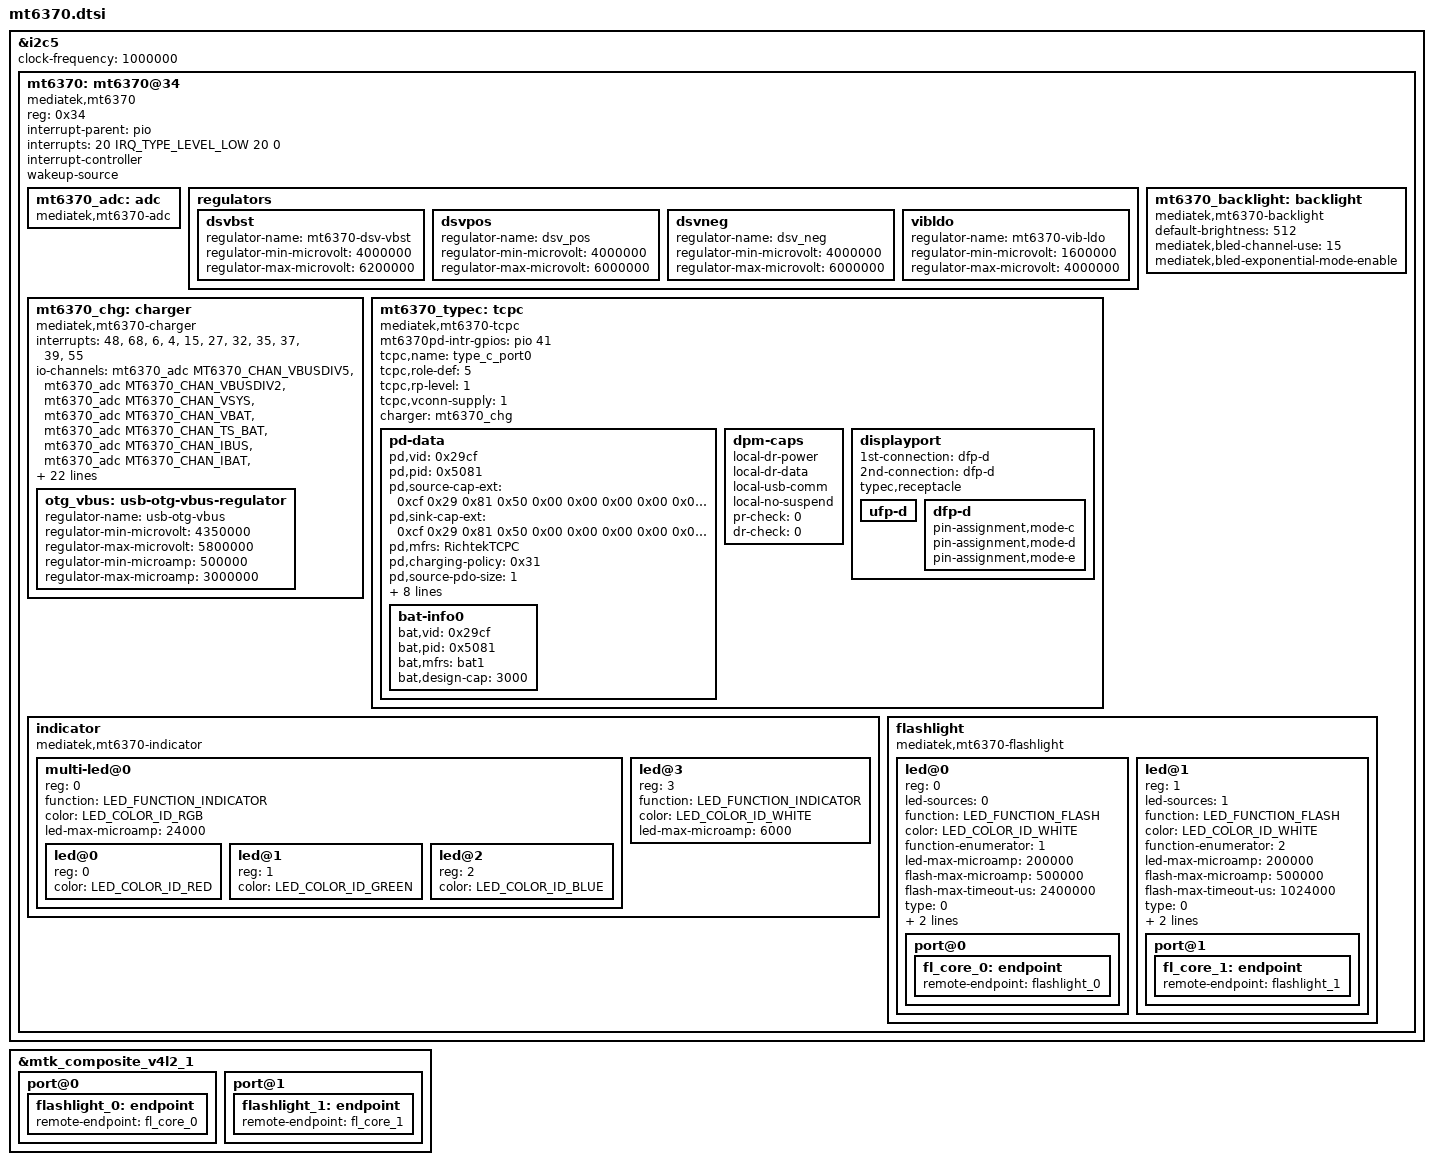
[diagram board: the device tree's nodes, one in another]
// SPDX-License-Identifier: (GPL-2.0 OR MIT)
/*
 * Copyright (c) 2021 MediaTek Inc.
 */

#include <dt-bindings/iio/adc/mediatek,mt6370_adc.h>
#include <dt-bindings/leds/common.h>

&i2c5 {
	clock-frequency = <1000000>;
	mt6370: mt6370@34 {
		compatible = "mediatek,mt6370";
		reg = <0x34>;
		status = "okay";
		interrupt-parent = <&pio>;
		interrupts = <20 IRQ_TYPE_LEVEL_LOW 20 0>;
		interrupt-controller;
		#interrupt-cells = <1>;
		wakeup-source;
		mt6370_adc: adc {
			#io-channel-cells = <1>;
			compatible = "mediatek,mt6370-adc";
		};

		regulators {
			dsvbst {
				regulator-name = "mt6370-dsv-vbst";
				regulator-min-microvolt = <4000000>;
				regulator-max-microvolt = <6200000>;
			};
			dsvpos {
				regulator-name = "dsv_pos";
				regulator-min-microvolt = <4000000>;
				regulator-max-microvolt = <6000000>;
			};
			dsvneg {
				regulator-name = "dsv_neg";
				regulator-min-microvolt = <4000000>;
				regulator-max-microvolt = <6000000>;
			};
			vibldo {
				regulator-name = "mt6370-vib-ldo";
				regulator-min-microvolt = <1600000>;
				regulator-max-microvolt = <4000000>;
			};
		};

		mt6370_chg: charger {
			compatible = "mediatek,mt6370-charger";
			interrupts = <48>, <68>, <6>, <4>, <15>, <27>, <32>, <35>, <37>, <39>, <55>;
			interrupt-names = "attach_i", "uvp_d_evt", "mivr", "treg",
					  "vbusov", "tmri", "aiclmeasi", "wdtmri",
					  "rechgi", "ieoci", "dcdti";
			io-channels = <&mt6370_adc MT6370_CHAN_VBUSDIV5>,
				      <&mt6370_adc MT6370_CHAN_VBUSDIV2>,
				      <&mt6370_adc MT6370_CHAN_VSYS>,
				      <&mt6370_adc MT6370_CHAN_VBAT>,
				      <&mt6370_adc MT6370_CHAN_TS_BAT>,
				      <&mt6370_adc MT6370_CHAN_IBUS>,
				      <&mt6370_adc MT6370_CHAN_IBAT>,
				      <&mt6370_adc MT6370_CHAN_CHG_VDDP>,
				      <&mt6370_adc MT6370_CHAN_TEMP_JC>;
			boot_mode = <&chosen>;
			charger_name = "primary_chg";
			load_switch_name = "primary_load_switch";
			ichg = <2000000>;       /* uA */
			aicr = <500000>;        /* uA */
			mivr = <4400000>;       /* uV */
			cv = <4350000>;         /* uA */
			ieoc = <150000>;        /* uA */
			safety_timer = <12>;    /* hour */
			dc_wdt = <4000000>;     /* us */
			ircmp_resistor = <25000>;       /* uohm */
			ircmp_vclamp = <32000>;         /* uV */
			enable_te;
			enable_wdt;
			enable_otg_wdt;
			lbp_hys_sel = <1>;      /* 0: 100mV, 1: 200mV */
			lbp_dt = <1>;           /* 0: 10ms, 1: 20ms */
			/* 2: 40ms, 3: 500us */
			/* with it: don't check 1.2v while PD/SD during BC12 */
			/* disable_vlgc; */
			/* with it: enable fast unknown TA detection */
			/* fast_unknown_ta_dect; */
			/* enable_polling; */
			/* with it: do post aicl measure */
			/* post_aicl; */
			//charger = <&mt6370_chg>;
			bc12_sel = <&mtk_ctd>;
			phys = <&u2port0 PHY_TYPE_USB2>;
			phy-names = "usb2-phy";
			usb = <&usb>;
			otg_vbus: usb-otg-vbus-regulator {
				//enable-gpios = <&gpio GPIOH_4 0>;
				regulator-name = "usb-otg-vbus";
				regulator-min-microvolt = <4350000>;
				regulator-max-microvolt = <5800000>;
				regulator-min-microamp = <500000>;
				regulator-max-microamp = <3000000>;
			};
		};

		mt6370_typec: tcpc {
			compatible = "mediatek,mt6370-tcpc";
			mt6370pd-intr-gpios = <&pio 41 0>;
			tcpc,name = "type_c_port0"; /* tcpc_device's name */
			/* 0: Unknown, 1: SNK, 2: SRC, 3: DRP, 4: Try.SRC, 5: Try.SNK */
			tcpc,role-def = <5>;
			tcpc,rp-level = <1>; /* 0: Default, 1: 1.5, 2: 3.0 */
			/* 0: Never, 1: Always, 2: EMarkOnly, 3: StartOnly */
			tcpc,vconn-supply = <1>;
			charger = <&mt6370_chg>;
			pd-data {
				pd,vid = <0x29cf>;
				pd,pid = <0x5081>;
				pd,source-cap-ext = /bits/ 8 <0xcf 0x29 0x81 0x50
							      0x00 0x00 0x00 0x00
							      0x00 0x00 0x00 0x00
							      0x00 0x00 0x00 0x00
							      0x00 0x00 0x00 0x00
							      0x00 0x00 0x01 0x07
							      0x00>;
				pd,sink-cap-ext = /bits/ 8 <0xcf 0x29 0x81 0x50
							    0x00 0x00 0x00 0x00
							    0x00 0x00 0x01 0x00
							    0x00 0x00 0x00 0x00
							    0x01 0x0b 0x01 0x0a
							    0x0a 0x00 0x00 0x00>;
				pd,mfrs = "RichtekTCPC";

				/*
				 *	VSAFE5V = 0, MAX_POWER = 1, CUSTOM = 2,
				 *	MAX_POWER_LV = 0x21, MAX_POWER_LVIC = 0x31
				 *	MAX_POWER_HV = 0x41, MAX_POWER_HVIC = 0x51
				 */
				pd,charging-policy = <0x31>;

				/*
				 * Fixed 5V, 500 mA <0x00019032>
				 * Fixed 5V, 1A <0x00019064>
				 * Fixed 5V, 2A <0x000190c8>
				 * Fixed 5V, 3A <0x0001912c>
				 * Fixed 9V, 500 mA <0x0002d032>
				 * Fixed 9V, 1A <0x0002d064>
				 * Fixed 9V, 2A <0x0002d0c8>
				 * Fixed 9V, 3A <0x0002d12c>
				 * Variable 5-9V, 1A <0x8642d064>
				 * Variable 5-9V, 2A <0x8642d0c8>
				 * Variable 5-9V, 3A <0x8642d12c>
				 */
				pd,source-pdo-size = <1>;
				pd,source-pdo-data = <0x00019096>; /* 5V, 1500 mA */
				pd,sink-pdo-size = <1>;
				pd,sink-pdo-data = <0x000190c8>;

				/*
				 * No DP, host + device
				 *	pd,id-vdo-size = <6>;
				 *	pd,id-vdo-data = <0xd14029cf 0x0 0x50810000
							  0x61000000 0x0 0x41000000>;
				 * With DP Sink capability
				 *	pd,id-vdo-size = <6>;
				 *	pd,id-vdo-data = <0xd54029cf 0x0 0x50810000
							  0x61000000 0x0 0x41000000>;
				 */

				pd,id-vdo-size = <6>;
				pd,id-vdo-data = <0xd14029cf 0x0 0x50810000
						  0x61000000 0x0 0x41000000>;

				bat,nr = <1>;
				pd,country-nr = <0>;

				bat-info0 {
					bat,vid = <0x29cf>;
					bat,pid = <0x5081>;
					bat,mfrs = "bat1";
					bat,design-cap = <3000>;
				};
			};
			dpm-caps {
				local-dr-power;
				local-dr-data;
				// local-ext-power;
				local-usb-comm;
				// local-usb-suspend;
				// local-high-cap;
				// local-give-back;
				local-no-suspend;

				/* With DP Source capability */
				// attempt-enter-dp-mode;
				// attempt-discover-cable;
				// attempt-discover-id;
				// attempt-discover-svids;

				/* 0: disable, 1: prefer-snk, 2: prefer-src */
				pr-check = <0>;
				// pr-reject-as-source;
				// pr-reject-as-sink;
				// pr-check-gp-source;
				// pr-check-gp-sink;

				/* 0: disable, 1: prefer-ufp, 2: prefer-dfp */
				dr-check = <0>;
				// dr-reject-as-dfp;
				// dr-reject-as-ufp;
			};
			displayport {
				/* connection type = "both", "ufp-d", "dfp-d" */
				1st-connection = "dfp-d";
				2nd-connection = "dfp-d";
				// usbr20-not-used;
				typec,receptacle;
				ufp-d {
					// pin-assignment,mode-c;
					// pin-assignment,mode-d;
					// pin-assignment,mode-e;
				};
				dfp-d {
					pin-assignment,mode-c;
					pin-assignment,mode-d;
					pin-assignment,mode-e;
				};
			};
		};

		mt6370_backlight: backlight {
			compatible = "mediatek,mt6370-backlight";
			default-brightness = <512>;
			mediatek,bled-channel-use = /bits/ 8 <15>;
			mediatek,bled-exponential-mode-enable;
		};

		indicator {
			compatible = "mediatek,mt6370-indicator";
			#address-cells = <1>;
			#size-cells = <0>;

			multi-led@0 {
				reg = <0>;
				function = LED_FUNCTION_INDICATOR;
				color = <LED_COLOR_ID_RGB>;
				led-max-microamp = <24000>;
				#address-cells = <1>;
				#size-cells = <0>;
				led@0 {
					reg = <0>;
					color = <LED_COLOR_ID_RED>;
				};
				led@1 {
					reg = <1>;
					color = <LED_COLOR_ID_GREEN>;
				};
				led@2 {
					reg = <2>;
					color = <LED_COLOR_ID_BLUE>;
				};
			};
			led@3 {
				reg = <3>;
				function = LED_FUNCTION_INDICATOR;
				color = <LED_COLOR_ID_WHITE>;
				led-max-microamp = <6000>;
			};
		};

		flashlight {
			compatible = "mediatek,mt6370-flashlight";
			#address-cells = <1>;
			#size-cells = <0>;

			led@0 {
				reg = <0>;
				led-sources = <0>;
				function = LED_FUNCTION_FLASH;
				color = <LED_COLOR_ID_WHITE>;
				function-enumerator = <1>;
				led-max-microamp = <200000>;
				flash-max-microamp = <500000>;
				flash-max-timeout-us = <2400000>;
				type = <0>;
				ct = <0>;
				part = <0>;
				port@0 {
					fl_core_0: endpoint {
						remote-endpoint = <&flashlight_0>;
					};
				};
			};
			led@1 {
				reg = <1>;
				led-sources = <1>;
				function = LED_FUNCTION_FLASH;
				color = <LED_COLOR_ID_WHITE>;
				function-enumerator = <2>;
				led-max-microamp = <200000>;
				flash-max-microamp = <500000>;
				flash-max-timeout-us = <1024000>;
				type = <0>;
				ct = <1>;
				part = <0>;
				port@1 {
					fl_core_1: endpoint {
						remote-endpoint = <&flashlight_1>;
					};
				};
			};
		};
	};
};

&mtk_composite_v4l2_1 {
	port@0 {
		flashlight_0: endpoint {
			remote-endpoint = <&fl_core_0>;
		};
	};
	port@1 {
		flashlight_1: endpoint {
			remote-endpoint = <&fl_core_1>;
		};
	};
};
